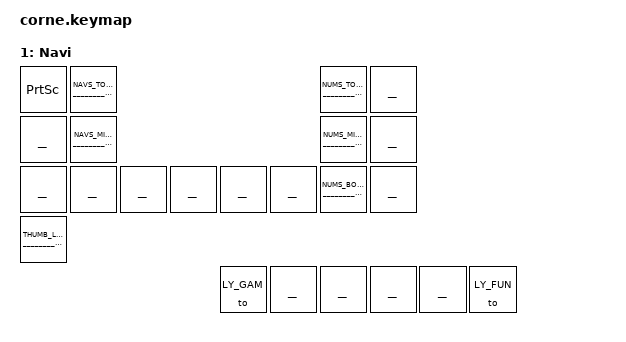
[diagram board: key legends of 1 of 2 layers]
#include <behaviors.dtsi>
#include <dt-bindings/zmk/keys.h>
#include <dt-bindings/zmk/bt.h>
#include <dt-bindings/zmk/ext_power.h>
#include <dt-bindings/zmk/outputs.h>
#include <dt-bindings/zmk/rgb.h>

#include "../zmk-nodefree-config/keypos_def/keypos_50keys.h"
#include "../zmk-nodefree-config/helper.h"

#include "../spacerock/spacerock.dtsi"

#define BASE_LAYER_kyria(name, \
    _____________________LT______________________, _____________________RT______________________, \
    _____________________LM______________________, _____________________RM______________________, \
    _____________________LB______________________, _____________________RB______________________ \

) ZMK_LAYER(name, \
    &kp TAB    _____________________LT______________________   _____________________RT______________________ ___ \
    HT_CTL_ESC _____________________LM______________________   _____________________RM______________________ HT_CTL_SQT \
    &sk LALT   _____________________LB______________________   _____________________RB______________________ &sk RALT \
                             HT_TOG_NAV HT_MEH_SPC &sk LSHFT   &sk RSHFT HT_MEH_ENT SMART_NUM \
)

BASE_LAYER_kyria(Game,
    ______________________QWERTY__LT______________________,   ______________________QWERTY__RT______________________,
    ______________________QWERTY__LM______________________,   ______________________QWERTY__RM______________________,
    ______________________QWERTY__LB______________________,   ______________________QWERTY__RB______________________
)

BASE_LAYER_kyria(Colemak,
    ____________________COLEMAK_DH__LT____________________,   ____________________COLEMAK_DH__RT____________________,
    ____________________COLEMAK_DH__LM____________________,   ____________________COLEMAK_DH__RM____________________,
    ____________________COLEMAK_DH__LB____________________,   ____________________COLEMAK_DH__RB____________________
)

#define HY_PG_UP &kp HY(PG_UP)
#define HY_PG_DN &kp HY(PG_DN)
ZMK_LAYER(Navi,
    &kp PSCRN  _______________________NAVS_TOP_______________________   _______________________NUMS_TOP_______________________ ___
    ___        _______________________NAVS_MID_______________________   _______________________NUMS_MID_______________________ ___
    ___        ___        ___        ___        ___        ___          _______________________NUMS_BOT_______________________ ___
    ____________________________THUMB_LEFT___________________________
                                            &to LY_GAM &kp UNDER  ___   ___        ___        &to LY_FUN
)
